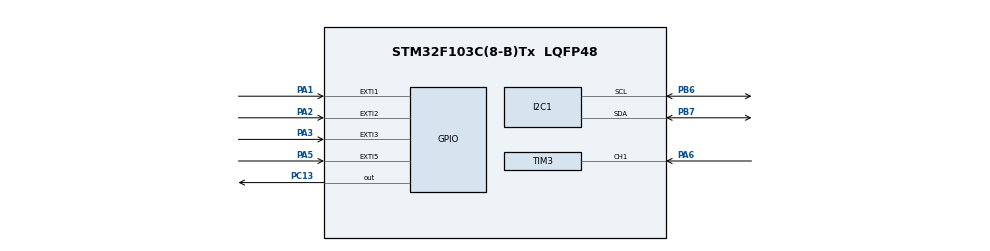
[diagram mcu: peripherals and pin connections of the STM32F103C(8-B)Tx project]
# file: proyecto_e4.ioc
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Mcu.Family=STM32F1
Mcu.Name=STM32F103C(8-B)Tx
Mcu.Package=LQFP48
NVIC.EXTI1_IRQn=true\:0\:0\:false\:false\:true\:true\:true\:true
NVIC.EXTI2_IRQn=true\:0\:0\:false\:false\:true\:true\:true\:true
NVIC.EXTI3_IRQn=true\:0\:0\:false\:false\:true\:true\:true\:true
NVIC.EXTI9_5_IRQn=true\:0\:0\:false\:false\:true\:true\:true\:true
NVIC.PriorityGroup=NVIC_PRIORITYGROUP_3
NVIC.TIM1_UP_IRQn=true\:0\:0\:false\:false\:true\:true\:true\:true
NVIC.TIM2_IRQn=true\:3\:1\:true\:false\:true\:true\:true\:true
NVIC.TIM3_IRQn=true\:0\:0\:false\:false\:true\:true\:true\:true
PA1.GPIO_PuPd=GPIO_NOPULL
PA1.Signal=GPXTI1
PA13.Mode=Serial_Wire
PA13.Signal=SYS_JTMS-SWDIO
PA14.Mode=Serial_Wire
PA14.Signal=SYS_JTCK-SWCLK
PA2.Signal=GPXTI2
PA3.Signal=GPXTI3
PA5.Signal=GPXTI5
PA6.Signal=S_TIM3_CH1
PB6.Mode=I2C
PB6.Signal=I2C1_SCL
PB7.Mode=I2C
PB7.Signal=I2C1_SDA
PC13-TAMPER-RTC.PinState=GPIO_PIN_SET
PC13-TAMPER-RTC.Signal=GPIO_Output
PD0-OSC_IN.Mode=HSE-External-Oscillator
PD0-OSC_IN.Signal=RCC_OSC_IN
PD1-OSC_OUT.Mode=HSE-External-Oscillator
PD1-OSC_OUT.Signal=RCC_OSC_OUT
ProjectManager.HeapSize=0x200
ProjectManager.StackSize=0x400
ProjectManager.TargetToolchain=STM32CubeIDE
RCC.APB1Freq_Value=8000000
RCC.APB2Freq_Value=8000000
RCC.SYSCLKSource=RCC_SYSCLKSOURCE_HSE
SH.S_TIM3_CH1.0=TIM3_CH1,PWM_Input_1
TIM1.Period=10
TIM1.Prescaler=8000-1
TIM2.Period=500
TIM2.Prescaler=8000-1
TIM3.ICPolarity_1=TIM_INPUTCHANNELPOLARITY_FALLING
TIM3.Period=6000-1
TIM3.Prescaler=8000-1
TIM3.TIM_MasterOutputTrigger=TIM_TRGO_RESET
VP_TIM1_VS_ClockSourceINT.Mode=Internal
VP_TIM2_VS_ClockSourceINT.Mode=Internal
VP_TIM3_VS_ClockSourceINT.Mode=Internal
board=custom

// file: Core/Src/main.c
/* USER CODE BEGIN Header */
/**
 ******************************************************************************
 * @file           : main.c
 * @brief          : Main program body
 ******************************************************************************
 * @attention
 *
 * Copyright (c) 2022 STMicroelectronics.
 * All rights reserved.
 *
 * This software is licensed under terms that can be found in the LICENSE file
 * in the root directory of this software component.
 * If no LICENSE file comes with this software, it is provided AS-IS.
 *
 ******************************************************************************
 */
/* USER CODE END Header */
#include "main.h"

/* USER CODE BEGIN Includes */

#include "bmp.h"
#include "i2c-lcd.h"
#include "loop.h"
#include "interrupts.h"
#include "stm32f1xx.h"

/* USER CODE END Includes */

/* USER CODE BEGIN PTD */
I2C_HandleTypeDef hi2c1;
TIM_HandleTypeDef htim2;
TIM_HandleTypeDef htim3;
/* USER CODE END PTD */

I2C_HandleTypeDef hi2c1;

TIM_HandleTypeDef htim1;
TIM_HandleTypeDef htim2;
TIM_HandleTypeDef htim3;

void SystemClock_Config(void);
static void MX_GPIO_Init(void);
static void MX_I2C1_Init(void);
static void MX_TIM2_Init(void);
static void MX_TIM3_Init(void);
static void MX_TIM1_Init(void);

int main(void)
{

  /* MCU Configuration--------------------------------------------------------*/

  /* Reset of all peripherals, Initializes the Flash interface and the Systick. */
  HAL_Init();

  /* Configure the system clock */
  SystemClock_Config();

  /* Initialize all configured peripherals */
  MX_GPIO_Init();
  MX_I2C1_Init();
  MX_TIM2_Init();
  MX_TIM3_Init();
  MX_TIM1_Init();
  /* USER CODE BEGIN 2 */

  bmpInit();
  lcdInit();
  HAL_TIM_Base_Start_IT(&htim2);

  HAL_TIM_IC_Start_IT(&htim3, TIM_CHANNEL_1);	//Inicializacion del timer 3 en modo input capture channel 1 (para rising edge)
  //HAL_TIM_Base_Start_IT(&htim3);
  HAL_TIM_IC_Start_IT(&htim3, TIM_CHANNEL_2); //channel 2 (que detecta los falling edge)
  /*Configuracion de los registros del timer 3*/
  //HAL_TIM_IC_Start(&htim3);

  /* USER CODE END 2 */

  /* Infinite loop */
  /* USER CODE BEGIN WHILE */
	while (1) {

		loop();

    /* USER CODE END WHILE */

	}
}

void SystemClock_Config(void)
{
  RCC_OscInitTypeDef RCC_OscInitStruct = {0};
  RCC_ClkInitTypeDef RCC_ClkInitStruct = {0};

  /** Initializes the RCC Oscillators according to the specified parameters
  * in the RCC_OscInitTypeDef structure.
  */
  RCC_OscInitStruct.OscillatorType = RCC_OSCILLATORTYPE_HSE;
  RCC_OscInitStruct.HSEState = RCC_HSE_ON;
  RCC_OscInitStruct.PLL.PLLState = RCC_PLL_NONE;
  if (HAL_RCC_OscConfig(&RCC_OscInitStruct) != HAL_OK)
  {
    Error_Handler();
  }

  /** Initializes the CPU, AHB and APB buses clocks
  */
  RCC_ClkInitStruct.ClockType = RCC_CLOCKTYPE_HCLK|RCC_CLOCKTYPE_SYSCLK
                              |RCC_CLOCKTYPE_PCLK1|RCC_CLOCKTYPE_PCLK2;
  RCC_ClkInitStruct.SYSCLKSource = RCC_SYSCLKSOURCE_HSE;
  RCC_ClkInitStruct.AHBCLKDivider = RCC_SYSCLK_DIV1;
  RCC_ClkInitStruct.APB1CLKDivider = RCC_HCLK_DIV1;
  RCC_ClkInitStruct.APB2CLKDivider = RCC_HCLK_DIV1;

  if (HAL_RCC_ClockConfig(&RCC_ClkInitStruct, FLASH_LATENCY_0) != HAL_OK)
  {
    Error_Handler();
  }
}

static void MX_I2C1_Init(void)
{

  hi2c1.Instance = I2C1;
  hi2c1.Init.ClockSpeed = 100000;
  hi2c1.Init.DutyCycle = I2C_DUTYCYCLE_2;
  hi2c1.Init.OwnAddress1 = 0;
  hi2c1.Init.AddressingMode = I2C_ADDRESSINGMODE_7BIT;
  hi2c1.Init.DualAddressMode = I2C_DUALADDRESS_DISABLE;
  hi2c1.Init.OwnAddress2 = 0;
  hi2c1.Init.GeneralCallMode = I2C_GENERALCALL_DISABLE;
  hi2c1.Init.NoStretchMode = I2C_NOSTRETCH_DISABLE;
  if (HAL_I2C_Init(&hi2c1) != HAL_OK)
  {
    Error_Handler();
  }

}

static void MX_TIM1_Init(void)
{

  TIM_ClockConfigTypeDef sClockSourceConfig = {0};
  TIM_MasterConfigTypeDef sMasterConfig = {0};

  htim1.Instance = TIM1;
  htim1.Init.Prescaler = 8000-1;
  htim1.Init.CounterMode = TIM_COUNTERMODE_UP;
  htim1.Init.Period = 100;
  htim1.Init.ClockDivision = TIM_CLOCKDIVISION_DIV1;
  htim1.Init.RepetitionCounter = 0;
  htim1.Init.AutoReloadPreload = TIM_AUTORELOAD_PRELOAD_DISABLE;
  if (HAL_TIM_Base_Init(&htim1) != HAL_OK)
  {
    Error_Handler();
  }
  sClockSourceConfig.ClockSource = TIM_CLOCKSOURCE_INTERNAL;
  if (HAL_TIM_ConfigClockSource(&htim1, &sClockSourceConfig) != HAL_OK)
  {
    Error_Handler();
  }
  sMasterConfig.MasterOutputTrigger = TIM_TRGO_RESET;
  sMasterConfig.MasterSlaveMode = TIM_MASTERSLAVEMODE_DISABLE;
  if (HAL_TIMEx_MasterConfigSynchronization(&htim1, &sMasterConfig) != HAL_OK)
  {
    Error_Handler();
  }

}

static void MX_TIM2_Init(void)
{

  TIM_ClockConfigTypeDef sClockSourceConfig = {0};
  TIM_MasterConfigTypeDef sMasterConfig = {0};

  htim2.Instance = TIM2;
  htim2.Init.Prescaler = 8000-1;
  htim2.Init.CounterMode = TIM_COUNTERMODE_UP;
  htim2.Init.Period = 500;
  htim2.Init.ClockDivision = TIM_CLOCKDIVISION_DIV1;
  htim2.Init.AutoReloadPreload = TIM_AUTORELOAD_PRELOAD_DISABLE;
  if (HAL_TIM_Base_Init(&htim2) != HAL_OK)
  {
    Error_Handler();
  }
  sClockSourceConfig.ClockSource = TIM_CLOCKSOURCE_INTERNAL;
  if (HAL_TIM_ConfigClockSource(&htim2, &sClockSourceConfig) != HAL_OK)
  {
    Error_Handler();
  }
  sMasterConfig.MasterOutputTrigger = TIM_TRGO_RESET;
  sMasterConfig.MasterSlaveMode = TIM_MASTERSLAVEMODE_DISABLE;
  if (HAL_TIMEx_MasterConfigSynchronization(&htim2, &sMasterConfig) != HAL_OK)
  {
    Error_Handler();
  }

}

static void MX_TIM3_Init(void)
{

  TIM_ClockConfigTypeDef sClockSourceConfig = {0};
  TIM_SlaveConfigTypeDef sSlaveConfig = {0};
  TIM_IC_InitTypeDef sConfigIC = {0};
  TIM_MasterConfigTypeDef sMasterConfig = {0};

  htim3.Instance = TIM3;
  htim3.Init.Prescaler = 8000-1;
  htim3.Init.CounterMode = TIM_COUNTERMODE_UP;
  htim3.Init.Period = 6000-1;
  htim3.Init.ClockDivision = TIM_CLOCKDIVISION_DIV1;
  htim3.Init.AutoReloadPreload = TIM_AUTORELOAD_PRELOAD_DISABLE;
  if (HAL_TIM_Base_Init(&htim3) != HAL_OK)
  {
    Error_Handler();
  }
  sClockSourceConfig.ClockSource = TIM_CLOCKSOURCE_INTERNAL;
  if (HAL_TIM_ConfigClockSource(&htim3, &sClockSourceConfig) != HAL_OK)
  {
    Error_Handler();
  }
  if (HAL_TIM_IC_Init(&htim3) != HAL_OK)
  {
    Error_Handler();
  }
  sSlaveConfig.SlaveMode = TIM_SLAVEMODE_RESET;
  sSlaveConfig.InputTrigger = TIM_TS_TI1FP1;
  sSlaveConfig.TriggerPolarity = TIM_INPUTCHANNELPOLARITY_FALLING;
  sSlaveConfig.TriggerPrescaler = TIM_ICPSC_DIV1;
  sSlaveConfig.TriggerFilter = 0;
  if (HAL_TIM_SlaveConfigSynchro(&htim3, &sSlaveConfig) != HAL_OK)
  {
    Error_Handler();
  }
  sConfigIC.ICPolarity = TIM_INPUTCHANNELPOLARITY_FALLING;
  sConfigIC.ICSelection = TIM_ICSELECTION_DIRECTTI;
  sConfigIC.ICPrescaler = TIM_ICPSC_DIV1;
  sConfigIC.ICFilter = 0;
  if (HAL_TIM_IC_ConfigChannel(&htim3, &sConfigIC, TIM_CHANNEL_1) != HAL_OK)
  {
    Error_Handler();
  }
  sConfigIC.ICPolarity = TIM_INPUTCHANNELPOLARITY_RISING;
  sConfigIC.ICSelection = TIM_ICSELECTION_INDIRECTTI;
  if (HAL_TIM_IC_ConfigChannel(&htim3, &sConfigIC, TIM_CHANNEL_2) != HAL_OK)
  {
    Error_Handler();
  }
  sMasterConfig.MasterOutputTrigger = TIM_TRGO_RESET;
  sMasterConfig.MasterSlaveMode = TIM_MASTERSLAVEMODE_DISABLE;
  if (HAL_TIMEx_MasterConfigSynchronization(&htim3, &sMasterConfig) != HAL_OK)
  {
    Error_Handler();
  }

}

static void MX_GPIO_Init(void)
{
  GPIO_InitTypeDef GPIO_InitStruct = {0};

  /* GPIO Ports Clock Enable */
  __HAL_RCC_GPIOC_CLK_ENABLE();
  __HAL_RCC_GPIOD_CLK_ENABLE();
  __HAL_RCC_GPIOA_CLK_ENABLE();
  __HAL_RCC_GPIOB_CLK_ENABLE();

  /*Configure GPIO pin Output Level */
  HAL_GPIO_WritePin(GPIOC, GPIO_PIN_13, GPIO_PIN_SET);

  /*Configure GPIO pin : PC13 */
  GPIO_InitStruct.Pin = GPIO_PIN_13;
  GPIO_InitStruct.Mode = GPIO_MODE_OUTPUT_PP;
  GPIO_InitStruct.Pull = GPIO_NOPULL;
  GPIO_InitStruct.Speed = GPIO_SPEED_FREQ_LOW;
  HAL_GPIO_Init(GPIOC, &GPIO_InitStruct);

  /*Configure GPIO pins : PA1 PA2 PA3 PA5 */
  GPIO_InitStruct.Pin = GPIO_PIN_1|GPIO_PIN_2|GPIO_PIN_3|GPIO_PIN_5;
  GPIO_InitStruct.Mode = GPIO_MODE_IT_RISING;
  GPIO_InitStruct.Pull = GPIO_NOPULL;
  HAL_GPIO_Init(GPIOA, &GPIO_InitStruct);

  /* EXTI interrupt init*/
  HAL_NVIC_SetPriority(EXTI1_IRQn, 0, 0);
  HAL_NVIC_EnableIRQ(EXTI1_IRQn);

  HAL_NVIC_SetPriority(EXTI2_IRQn, 0, 0);
  HAL_NVIC_EnableIRQ(EXTI2_IRQn);

  HAL_NVIC_SetPriority(EXTI3_IRQn, 0, 0);
  HAL_NVIC_EnableIRQ(EXTI3_IRQn);

  HAL_NVIC_SetPriority(EXTI9_5_IRQn, 0, 0);
  HAL_NVIC_EnableIRQ(EXTI9_5_IRQn);

}

/* USER CODE BEGIN 4 */
/* INTERUPCIONES */

/*ISR del timer 2 que toglea el led cada medio segundo*/

/*ISR del timer 3 canal 1 (rising edge). Para el boton BACK*/

/*
 Cuando hay un flanco de subida el contador del timer 3 se resetea (CHANNEL 1 y CHANNEL 2 usan el mismo contador).
 En ese primer momento ICValue tomará el valor capturado del contador que estará en cero. Luego el contador sigue contando normalmente.
 En el flanco de bajada el channel 2 activa la ISR del channel 1, se vuelve a capturar el contador en ICValue que ahora será
 distinto de cero. Por lo tanto ahora se accede al segundo "if". Aquí simplemente se lee el valor capturado del channel 2 que en ese
 instante coincidirá con el de ICValue.

 */

/* USER CODE END 4 */

void Error_Handler(void)
{
	__disable_irq();
	while (1) {
	}
}
